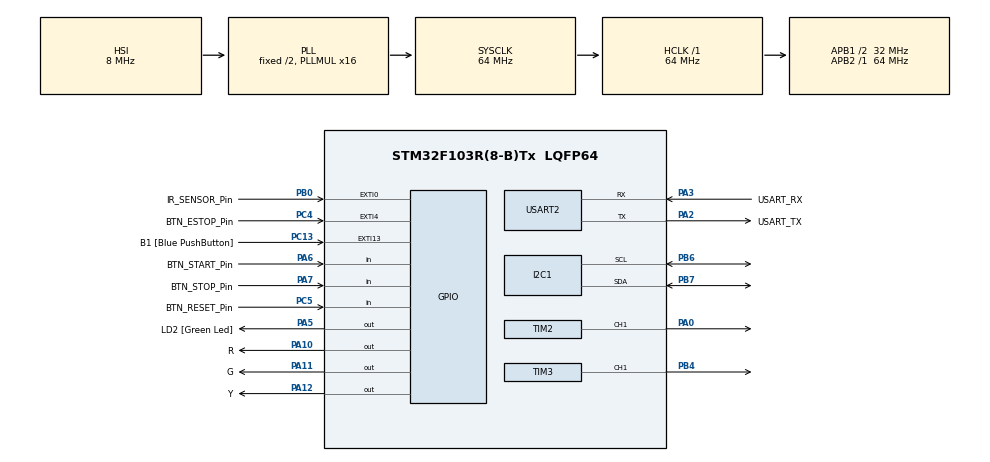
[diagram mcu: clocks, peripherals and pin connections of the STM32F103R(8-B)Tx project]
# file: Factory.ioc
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FREERTOS.INCLUDE_xTimerPendFunctionCall=1
FREERTOS.Tasks01=defaultTask,0,128,StartDefaultTask,Default,NULL,Dynamic,NULL,NULL
FREERTOS.configTIMER_TASK_PRIORITY=5
FREERTOS.configUSE_TIMERS=1
Mcu.Family=STM32F1
Mcu.Name=STM32F103R(8-B)Tx
Mcu.Package=LQFP64
NVIC.EXTI15_10_IRQn=true\:5\:0\:false\:false\:true\:true\:true\:true\:true
NVIC.PriorityGroup=NVIC_PRIORITYGROUP_4
NVIC.TIM2_IRQn=true\:5\:0\:false\:false\:true\:true\:true\:true\:true
PA0-WKUP.Signal=S_TIM2_CH1_ETR
PA10.GPIO_Label=R
PA10.PinState=GPIO_PIN_RESET
PA10.Signal=GPIO_Output
PA11.GPIO_Label=G
PA11.PinState=GPIO_PIN_RESET
PA11.Signal=GPIO_Output
PA12.GPIO_Label=Y
PA12.PinState=GPIO_PIN_RESET
PA12.Signal=GPIO_Output
PA13.GPIO_Label=TMS
PA13.Mode=Serial_Wire
PA13.Signal=SYS_JTMS-SWDIO
PA14.GPIO_Label=TCK
PA14.Mode=Serial_Wire
PA14.Signal=SYS_JTCK-SWCLK
PA2.GPIO_Label=USART_TX
PA2.GPIO_Mode=GPIO_MODE_AF_PP
PA2.GPIO_PuPd=GPIO_NOPULL
PA2.GPIO_Speed=GPIO_SPEED_FREQ_LOW
PA2.Mode=Asynchronous
PA2.Signal=USART2_TX
PA3.GPIO_Label=USART_RX
PA3.GPIO_Mode=GPIO_MODE_AF_PP
PA3.GPIO_PuPd=GPIO_NOPULL
PA3.GPIO_Speed=GPIO_SPEED_FREQ_LOW
PA3.Mode=Asynchronous
PA3.Signal=USART2_RX
PA5.GPIO_Label=LD2 [Green Led]
PA5.GPIO_ModeDefaultOutputPP=GPIO_MODE_OUTPUT_PP
PA5.GPIO_PuPd=GPIO_NOPULL
PA5.GPIO_Speed=GPIO_SPEED_FREQ_LOW
PA5.Signal=GPIO_Output
PA6.GPIO_Label=BTN_START_Pin
PA6.GPIO_PuPd=GPIO_PULLUP
PA6.Signal=GPIO_Input
PA7.GPIO_Label=BTN_STOP_Pin
PA7.GPIO_PuPd=GPIO_PULLUP
PA7.Signal=GPIO_Input
PB0.GPIO_Label=IR_SENSOR_Pin
PB0.GPIO_ModeDefaultEXTI=GPIO_MODE_EVT_FALLING
PB0.Signal=GPXTI0
PB3.GPIO_Label=SWO
PB3.Signal=SYS_JTDO-TRACESWO
PB4.Signal=S_TIM3_CH1
PB6.Mode=I2C
PB6.Signal=I2C1_SCL
PB7.Mode=I2C
PB7.Signal=I2C1_SDA
PC13-TAMPER-RTC.GPIO_Label=B1 [Blue PushButton]
PC13-TAMPER-RTC.GPIO_PuPd=GPIO_NOPULL
PC13-TAMPER-RTC.Signal=GPXTI13
PC14-OSC32_IN.Mode=LSE-External-Oscillator
PC14-OSC32_IN.Signal=RCC_OSC32_IN
PC15-OSC32_OUT.Mode=LSE-External-Oscillator
PC15-OSC32_OUT.Signal=RCC_OSC32_OUT
PC4.GPIO_Label=BTN_ESTOP_Pin
PC4.GPIO_ModeDefaultEXTI=GPIO_MODE_EVT_FALLING
PC4.GPIO_PuPd=GPIO_PULLUP
PC4.Signal=GPXTI4
PC5.GPIO_Label=BTN_RESET_Pin
PC5.GPIO_PuPd=GPIO_PULLUP
PC5.Signal=GPIO_Input
PD0-OSC_IN.Mode=HSE-External-Clock-Source
PD0-OSC_IN.Signal=RCC_OSC_IN
PD1-OSC_OUT.Mode=HSE-External-Clock-Source
PD1-OSC_OUT.Signal=RCC_OSC_OUT
ProjectManager.HeapSize=0x200
ProjectManager.StackSize=0x400
ProjectManager.TargetToolchain=STM32CubeIDE
RCC.AHBFreq_Value=64000000
RCC.APB1CLKDivider=RCC_HCLK_DIV2
RCC.APB1Freq_Value=32000000
RCC.APB1TimFreq_Value=64000000
RCC.APB2Freq_Value=64000000
RCC.APB2TimFreq_Value=64000000
RCC.HCLKFreq_Value=64000000
RCC.PLLMUL=RCC_PLL_MUL16
RCC.RTCClockSelection=RCC_RTCCLKSOURCE_LSE
RCC.SYSCLKFreq_VALUE=64000000
RCC.SYSCLKSource=RCC_SYSCLKSOURCE_PLLCLK
RCC.USBFreq_Value=64000000
SH.S_TIM2_CH1_ETR.0=TIM2_CH1,PWM Generation1 CH1
SH.S_TIM3_CH1.0=TIM3_CH1,PWM Generation1 CH1
TIM2.Channel-PWM\ Generation1\ CH1=TIM_CHANNEL_1
TIM2.Period=19999
TIM2.Prescaler=63
TIM2.Pulse-PWM\ Generation1\ CH1=1500
TIM3.Channel-PWM\ Generation1\ CH1=TIM_CHANNEL_1
TIM3.Period=3199
USART2.VirtualMode=VM_ASYNC
VP_FREERTOS_VS_CMSIS_V1.Mode=CMSIS_V1
VP_TIM2_VS_ClockSourceINT.Mode=Internal
board=NUCLEO-F103RB

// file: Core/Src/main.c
/* USER CODE BEGIN Header */
/**
  ******************************************************************************
  * @file           : main.c
  * @brief          : Main program body
  ******************************************************************************
  * @attention
  *
  * Copyright (c) 2025 STMicroelectronics.
  * All rights reserved.
  *
  * This software is licensed under terms that can be found in the LICENSE file
  * in the root directory of this software component.
  * If no LICENSE file comes with this software, it is provided AS-IS.
  *
  ******************************************************************************
  */
//ggg
/* USER CODE END Header */
#include "main.h"
#include "cmsis_os.h"
#include "i2c.h"
#include "tim.h"
#include "usart.h"
#include "gpio.h"

void SystemClock_Config(void);
void MX_FREERTOS_Init(void);

int main(void)
{

  /* MCU Configuration--------------------------------------------------------*/

  /* Reset of all peripherals, Initializes the Flash interface and the Systick. */
  HAL_Init();

  /* Configure the system clock */
  SystemClock_Config();

  /* Initialize all configured peripherals */
  MX_GPIO_Init();
  MX_USART2_UART_Init();
  MX_TIM2_Init();
  MX_TIM3_Init();
  MX_I2C1_Init();

  /* Call init function for freertos objects (in cmsis_os2.c) */
  MX_FREERTOS_Init();

  /* Start scheduler */
  osKernelStart();

  /* We should never get here as control is now taken by the scheduler */

  /* Infinite loop */
  while (1)
  {

  }
}

void SystemClock_Config(void)
{
  RCC_OscInitTypeDef RCC_OscInitStruct = {0};
  RCC_ClkInitTypeDef RCC_ClkInitStruct = {0};

  /** Initializes the RCC Oscillators according to the specified parameters
  * in the RCC_OscInitTypeDef structure.
  */
  RCC_OscInitStruct.OscillatorType = RCC_OSCILLATORTYPE_HSI;
  RCC_OscInitStruct.HSIState = RCC_HSI_ON;
  RCC_OscInitStruct.HSICalibrationValue = RCC_HSICALIBRATION_DEFAULT;
  RCC_OscInitStruct.PLL.PLLState = RCC_PLL_ON;
  RCC_OscInitStruct.PLL.PLLSource = RCC_PLLSOURCE_HSI_DIV2;
  RCC_OscInitStruct.PLL.PLLMUL = RCC_PLL_MUL16;
  if (HAL_RCC_OscConfig(&RCC_OscInitStruct) != HAL_OK)
  {
    Error_Handler();
  }

  /** Initializes the CPU, AHB and APB buses clocks
  */
  RCC_ClkInitStruct.ClockType = RCC_CLOCKTYPE_HCLK|RCC_CLOCKTYPE_SYSCLK
                              |RCC_CLOCKTYPE_PCLK1|RCC_CLOCKTYPE_PCLK2;
  RCC_ClkInitStruct.SYSCLKSource = RCC_SYSCLKSOURCE_PLLCLK;
  RCC_ClkInitStruct.AHBCLKDivider = RCC_SYSCLK_DIV1;
  RCC_ClkInitStruct.APB1CLKDivider = RCC_HCLK_DIV2;
  RCC_ClkInitStruct.APB2CLKDivider = RCC_HCLK_DIV1;

  if (HAL_RCC_ClockConfig(&RCC_ClkInitStruct, FLASH_LATENCY_2) != HAL_OK)
  {
    Error_Handler();
  }
}

void Error_Handler(void)
{
  __disable_irq();
  while (1)
  {
  }
}

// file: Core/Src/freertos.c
/* USER CODE BEGIN Header */
/**
  ******************************************************************************
  * File Name          : freertos.c
  * Description        : Code for freertos applications
  ******************************************************************************
  * @attention
  *
  * Copyright (c) 2025 STMicroelectronics.
  * All rights reserved.
  *
  * This software is licensed under terms that can be found in the LICENSE file
  * in the root directory of this software component.
  * If no LICENSE file comes with this software, it is provided AS-IS.
  *
  ******************************************************************************
  */
/* USER CODE END Header */

#include "FreeRTOS.h"
#include "task.h"
#include "main.h"
#include "cmsis_os.h"

/* USER CODE BEGIN Includes */
#include "app_os.h"
/* USER CODE END Includes */

osThreadId defaultTaskHandle;

void StartDefaultTask(void const * argument);

void MX_FREERTOS_Init(void); /* (MISRA C 2004 rule 8.1) */

/* GetIdleTaskMemory prototype (linked to static allocation support) */
void vApplicationGetIdleTaskMemory( StaticTask_t **ppxIdleTaskTCBBuffer, StackType_t **ppxIdleTaskStackBuffer, uint32_t *pulIdleTaskStackSize );

/* GetTimerTaskMemory prototype (linked to static allocation support) */
void vApplicationGetTimerTaskMemory( StaticTask_t **ppxTimerTaskTCBBuffer, StackType_t **ppxTimerTaskStackBuffer, uint32_t *pulTimerTaskStackSize );

/* USER CODE BEGIN GET_IDLE_TASK_MEMORY */
static StaticTask_t xIdleTaskTCBBuffer;
static StackType_t xIdleStack[configMINIMAL_STACK_SIZE];

void vApplicationGetIdleTaskMemory( StaticTask_t **ppxIdleTaskTCBBuffer, StackType_t **ppxIdleTaskStackBuffer, uint32_t *pulIdleTaskStackSize )
{
  *ppxIdleTaskTCBBuffer = &xIdleTaskTCBBuffer;
  *ppxIdleTaskStackBuffer = &xIdleStack[0];
  *pulIdleTaskStackSize = configMINIMAL_STACK_SIZE;
  /* place for user code */
}
/* USER CODE END GET_IDLE_TASK_MEMORY */

/* USER CODE BEGIN GET_TIMER_TASK_MEMORY */
static StaticTask_t xTimerTaskTCBBuffer;
static StackType_t xTimerStack[configTIMER_TASK_STACK_DEPTH];

void vApplicationGetTimerTaskMemory( StaticTask_t **ppxTimerTaskTCBBuffer, StackType_t **ppxTimerTaskStackBuffer, uint32_t *pulTimerTaskStackSize )
{
  *ppxTimerTaskTCBBuffer = &xTimerTaskTCBBuffer;
  *ppxTimerTaskStackBuffer = &xTimerStack[0];
  *pulTimerTaskStackSize = configTIMER_TASK_STACK_DEPTH;
  /* place for user code */
}
/* USER CODE END GET_TIMER_TASK_MEMORY */

void MX_FREERTOS_Init(void) {
  /* USER CODE BEGIN Init */
	AppOS_CreateObjects(); //이벤트 그룹, 큐 생성
	AppOS_CreateTasks(); //Task 생성
  /* USER CODE END Init */

  /* Create the thread(s) */
  /* definition and creation of defaultTask */
  osThreadDef(defaultTask, StartDefaultTask, osPriorityNormal, 0, 128);
  defaultTaskHandle = osThreadCreate(osThread(defaultTask), NULL);

}

void StartDefaultTask(void const * argument)
{
  for(;;)
  {
    osDelay(1);
  }
}
